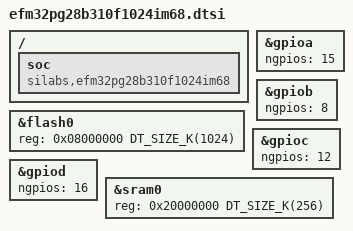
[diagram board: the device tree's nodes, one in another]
/*
 * Copyright (c) 2025 Christoph Jans
 * Copyright (c) 2025 Silicon Laboratories Inc.
 *
 * SPDX-License-Identifier: Apache-2.0
 */

#include <mem.h>
#include <silabs/xg28/efm32pg28.dtsi>

/ {
	soc {
		compatible = "silabs,efm32pg28b310f1024im68", "silabs,efm32pg28", "silabs,xg28",
			     "silabs,efm32", "simple-bus";
	};
};

&flash0 {
	reg = <0x08000000 DT_SIZE_K(1024)>;
};

&gpioa {
	ngpios = <15>;
};

&gpiob {
	ngpios = <8>;
};

&gpioc {
	ngpios = <12>;
};

&gpiod {
	ngpios = <16>;
};

&sram0 {
	reg = <0x20000000 DT_SIZE_K(256)>;
};
